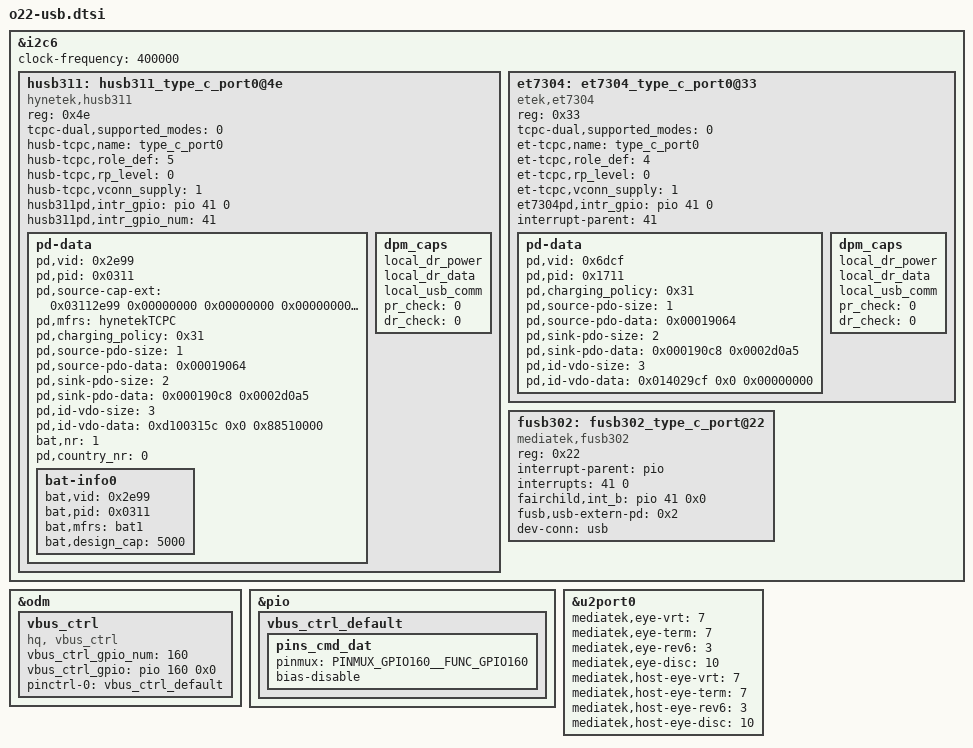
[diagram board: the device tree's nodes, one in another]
/* hs14 code for SR-AL6528A-01-307 by wenyaqi at 2022/08/30 start */
&i2c6 {
	clock-frequency = <400000>;
	husb311:husb311_type_c_port0@4e{
		compatible = "hynetek,husb311";
		reg = <0x4e>;
		status = "okay";
		tcpc-dual,supported_modes = <0>; /* 0: dfp/ufp, */
						 /* 1: dfp, 2: ufp */
		husb-tcpc,name = "type_c_port0"; /* tcpc_device's name */
		husb-tcpc,role_def = <5>; /* 1: SNK Only, 2: SRC Only, 3: DRP, */
					/* 4: Try.SRC, 5: Try.SNK */
		husb-tcpc,rp_level = <0>; /* 0: Default, 1: 1.5, 2: 3.0 */
		husb-tcpc,vconn_supply  = <1>;  /* 0: Never, 1: Always, */
					      /* 2: EMarkOnly, 3: StartOnly */
		husb311pd,intr_gpio = <&pio 41 0>;
		husb311pd,intr_gpio_num = <41>;
		/* hs14 code for SR-AL6528A-01-322 by wenyaqi at 2022/09/15 start */
		pd-data {
			pd,vid = <0x2e99>;
			pd,pid = <0x0311>;
			pd,source-cap-ext = <0x03112e99 0x00000000 0x00000000
					     0x00000000 0x00000000 0x02000000>;
			pd,mfrs = "hynetekTCPC";

			/*
			 *	VSAFE5V = 0, MAX_POWER = 1, CUSTOM = 2,
			 *	MAX_POWER_LV = 0x21, MAX_POWER_LVIC = 0x31
			 *	MAX_POWER_HV = 0x41, MAX_POWER_HVIC = 0x51
			 */
			pd,charging_policy= <0x31>;

			/*
			 * Fixed 5V, 500 mA <0x00019032>
			 * Fixed 5V, 1A <0x00019064>
			 * Fixed 5V, 2A <0x000190c8>
			 * Fixed 5V, 3A <0x0001912c>
			 * Fixed 9V, 500 mA <0x0002d032>
			 * Fixed 9V, 1A <0x0002d064>
			 * Fixed 9V, 2A <0x0002d0c8>
			 * Fixed 9V, 3A <0x0002d12c>
			 * Variable 5-9V, 1A <0x8642d064>
			 * Variable 5-9V, 2A <0x8642d0c8>
			 * Variable 5-9V, 3A <0x8642d12c>
			 * PPS 3V~5.9V, 3A <0xC0761E3C>
			 */
			pd,source-pdo-size = <1>;
			pd,source-pdo-data = <0x00019064>;
			pd,sink-pdo-size = <2>;
			pd,sink-pdo-data = <0x000190c8 0x0002d0a5>; // 9V1.65A

			/*
			 * No DP, host + device
			 *	pd,id-vdo-size = <3>;
			 *	pd,id-vdo-data = <0xd10029cf 0x0 0x17110000>;
			 * With DP
			 *	pd,id-vdo-size = <3>;
			 *	pd,id-vdo-data = <0xd60029cf 0x0 0x17110000
			 */

			pd,id-vdo-size = <3>;
			pd,id-vdo-data = <0xd100315c 0x0 0x88510000>;

			bat,nr = <1>;
			pd,country_nr = <0>;

			bat-info0 {
				bat,vid = <0x2e99>;
				bat,pid = <0x0311>;
				bat,mfrs = "bat1";
				bat,design_cap = <5000>;
			};

			//bat-info1 {
			//	bat,vid = <0x8abc>;
			//	bat,pid = <0x5234>;
			//	bat,mfrs = "bat2";
			//	bat,design_cap = <4000>;
			//};

			//country0 {
			//	pd,country_code = <0x5457>;
			//	pd,country_len = <2>; /* max len = 26 */
			//	pd,country_data = <0xff 0xff>;
			//};

			//country1 {
			//	pd,country_code = <0x5553>;
			//	pd,country_len = <3>; /* max len = 26 */
			//	pd,country_data = <0xf1 0xf2 0xf3>;
			//};
		};

		dpm_caps {
			local_dr_power;
			local_dr_data;
			//local_ext_power;
			local_usb_comm;
			//local_usb_suspend;
			//local_high_cap;
			//local_give_back;
			/* hs14 code for AL6528A-440 by wenyaqi at 2022/10/27 start */
			//local_no_suspend;
			//local_vconn_supply;
			/* hs14 code for AL6528A-440 by wenyaqi at 2022/10/27 end */

			//attemp_discover_cable_dfp;
			// attemp_enter_dp_mode;
			// attemp_discover_cable;
			// attemp_discover_id;

			/* 0: disable, 1: prefer_snk, 2: prefer_src */
			pr_check = <0>;
			/* hs14 code for SR-AL6528A-01-253 by chengyuanhang at 2022/09/23 start */
			//pr_reject_as_source;
			//pr_reject_as_sink;
			/* hs14 code for SR-AL6528A-01-253 by chengyuanhang at 2022/09/23 end */

			//pr_check_gp_source;
			//pr_check_gp_sink;

			/* 0: disable, 1: prefer_ufp, 2: prefer_dfp */
			dr_check = <0>;
			//dr_reject_as_dfp;
			//dr_reject_as_ufp;
		};
		/* hs14 code for SR-AL6528A-01-322 by wenyaqi at 2022/09/15 end */
	};

	/* hs14 code for SR-AL6528A-01-309 by wenyaqi at 2022/09/11 start */
	et7304:et7304_type_c_port0@33 {
		compatible = "etek,et7304";
		reg = <0x33>; /* should be 4e in fact */
		status = "okay";
		tcpc-dual,supported_modes = <0>; /* 0: dfp/ufp, */
						 /* 1: dfp, 2: ufp */
		et-tcpc,name = "type_c_port0"; /* tcpc_device's name */
		et-tcpc,role_def = <4>; /* 0: SNK Only, 1: SRC Only, 2: DRP, */
					/* 3: Try.SRC, 4: Try.SNK */
		et-tcpc,rp_level = <0>; /* 0: Default, 1: 1.5, 2: 3.0 */
		et-tcpc,vconn_supply  = <1>;  /* 0: Never, 1: Always, */
					      /* 2: EMarkOnly, 3: StartOnly */
		et7304pd,intr_gpio = <&pio 41 0>;
		interrupt-parent = <41>;
		/* hs14 code for SR-AL6528A-01-322 by wenyaqi at 2022/09/19 start */
		pd-data {
			pd,vid = <0x6dcf>;
			pd,pid = <0x1711>;
			/*
			 *	VSAFE5V = 0, MAX_POWER = 1, CUSTOM = 2,
			 *	MAX_POWER_LV = 0x21, MAX_POWER_LVIC = 0x31
			 *	MAX_POWER_HV = 0x41, MAX_POWER_HVIC = 0x51
			 */
			pd,charging_policy= <0x31>;

			/*
			 * Fixed 5V, 500 mA <0x00019032>
			 * Fixed 5V, 1A <0x00019064>
			 * Fixed 5V, 2A <0x000190c8>
			 * Fixed 5V, 3A <0x0001912c>
			 * Fixed 9V, 500 mA <0x0002d032>
			 * Fixed 9V, 1A <0x0002d064>
			 * Fixed 9V, 2A <0x0002d0c8>
			 * Fixed 9V, 3A <0x0002d12c>
			 * Variable 5-9V, 1A <0x8642d064>
			 * Variable 5-9V, 2A <0x8642d0c8>
			 * Variable 5-9V, 3A <0x8642d12c>
			 * PPS 3V~5.9V, 3A <0xC0761E3C>
			 */
			pd,source-pdo-size = <1>;
			pd,source-pdo-data = <0x00019064>;
			/* hs14 code for SR-AL6528A-01-322 by wenyaqi at 2022/09/20 start */
			pd,sink-pdo-size = <2>;
			pd,sink-pdo-data = <0x000190c8 0x0002d0a5>; // 9V1.65A
			/* hs14 code for SR-AL6528A-01-322 by wenyaqi at 2022/09/20 start */

			/*
			 * No DP, host + device
			 *	pd,id-vdo-size = <6>;
			 *	pd,id-vdo-data = <0xd14029cf 0x0 0x17110000
						  0x41800000 0x0 0x21800000>;
			 * With DP
			 *	pd,id-vdo-size = <6>;
			 *	pd,id-vdo-data = <0xd54029cf 0x0 0x17110000
						  0x41800000 0x0 0x21800000>;
			 */

			pd,id-vdo-size = <3>;
			pd,id-vdo-data = <0x014029cf 0x0 0x00000000>;
		};

		dpm_caps {
			local_dr_power;
			local_dr_data;
			//local_ext_power;
			/* hs14 code for AL6528A-440 by wenyaqi at 2022/10/27 start */
			local_usb_comm;
			/* hs14 code for AL6528A-440 by wenyaqi at 2022/10/27 end */
			//local_usb_suspend;
			//local_high_cap;
			//local_give_back;
			//local_no_suspend;
			//local_vconn_supply;

			//attemp_discover_cable_dfp;
			//attemp_enter_dp_mode;
			//attemp_discover_cable;
			//attemp_discover_id;

			/* 0: disable, 1: prefer_snk, 2: prefer_src */
			pr_check = <0>;
			//pr_reject_as_source;
			//pr_reject_as_sink;
			//pr_check_gp_source;
			//pr_check_gp_sink;

			/* 0: disable, 1: prefer_ufp, 2: prefer_dfp */
			dr_check = <0>;
			//dr_reject_as_dfp;
			//dr_reject_as_ufp;
		};
		/* hs14 code for SR-AL6528A-01-322 by wenyaqi at 2022/09/19 end */
	};
	/* hs14 code for SR-AL6528A-01-309 by wenyaqi at 2022/09/11 end */

	/* hs14 code for SR-AL6528A-01-308 by wenyaqi at 2022/09/09 start */
	fusb302:fusb302_type_c_port@22 {
		compatible = "mediatek,fusb302";
		reg = <0x22>;
		interrupt-parent = <&pio>;
		interrupts = <41 0>;
		fairchild,int_b = <&pio 41 0x0>;
		fusb,usb-extern-pd = /bits/ 8 <0x2>;
		status = "okay";
		dev-conn = <&usb>;
	};
	/* hs14 code for SR-AL6528A-01-308 by wenyaqi at 2022/09/09 end */
};
/* hs14 code for SR-AL6528A-01-307 by wenyaqi at 2022/08/30 end */

/* hs14 code for SR-AL6528A-01-305 by shanxinkai at 2022/09/06 start */
&odm {
	/* VBUS control */
	vbus_ctrl: vbus_ctrl {
		compatible = "hq, vbus_ctrl";
		vbus_ctrl_gpio_num = <160>;
		vbus_ctrl_gpio = <&pio 160 0x0>;
		pinctrl-names = "default";
		pinctrl-0 = <&vbus_ctrl_default>;
	};
};

&pio {
	vbus_ctrl_default: vbus_ctrl_default {
		pins_cmd_dat {
			pinmux = <PINMUX_GPIO160__FUNC_GPIO160>;
			bias-disable;
		};
	};
};
/* hs14 code for SR-AL6528A-01-305 by shanxinkai at 2022/09/06 end */

/* hs14 code for AL6528A-30 by wenyaqi at 2022/09/11 start */
&u2port0 {
	mediatek,eye-vrt = <7>; /* 0~7 */
	mediatek,eye-term = <7>; /* 0~7 */
	mediatek,eye-rev6 = <3>; /* 0~3 */
	/* hs14 code for SR-AL6528A-01-253 by chengyuanhang at 2022/09/23 start */
	mediatek,eye-disc = <10>; /* 0~8 */
	/* hs14 code for SR-AL6528A-01-253 by chengyuanhang at 2022/09/23 end */
	mediatek,host-eye-vrt = <7>; /* 0~7 */
	mediatek,host-eye-term = <7>; /* 0~7 */
	mediatek,host-eye-rev6 = <3>; /* 0~3 */
	/* hs14 code for SR-AL6528A-01-253 by chengyuanhang at 2022/09/23 start */
	mediatek,host-eye-disc = <10>; /* 0~8 */
	/* hs14 code for SR-AL6528A-01-253 by chengyuanhang at 2022/09/23 end */
};
/* hs14 code for AL6528A-30 by wenyaqi at 2022/09/11 end */
